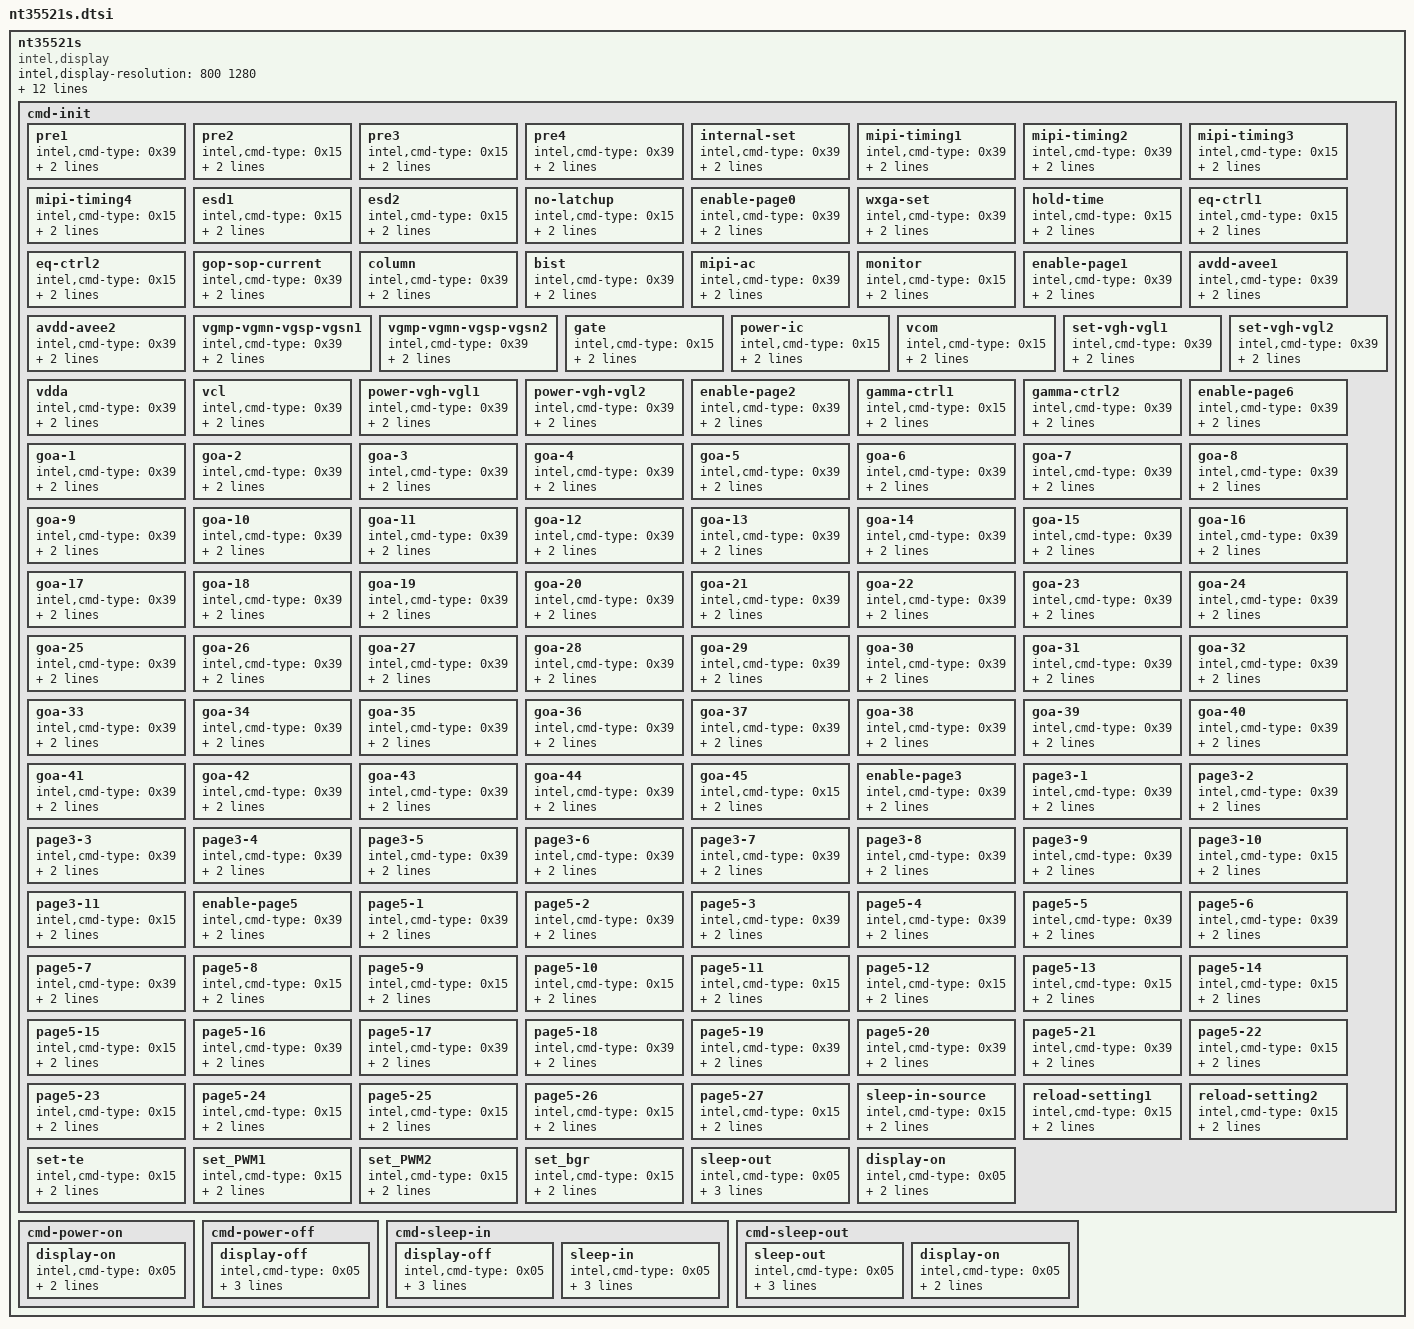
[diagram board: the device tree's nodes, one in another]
	nt35521s {
		compatible = "intel,display";
		intel,display-resolution= <800 1280>;
		intel,display-dpi= <251 251>;

		/* MIPI-DSI video mode settings */
		intel,display-vid-hfp-hs-bytes = <80>;
		intel,display-vid-hbp-hs-bytes = <80>;
		intel,display-vid-hsa-hs-bytes = <2>;
		intel,display-vid-vfp-lines = <20>;
		intel,display-vid-vbp-lines = <20>;
		intel,display-vid-vsa-lines = <2>;

		intel,display-vid-mode = "pulses";
		intel,display-vid-id = <0>;
		intel,display-vid-pixel = "24packed";
		intel,display-vid-fill_buf_to = <0x1F>;

		intel,display-reset = <1 1 0 5 1 50>;

		cmd-init {
			pre1 {
				intel,cmd-type = <0x39>;
				intel,cmd-data = <0xFF 0xAA 0x55 0x25 0x01>;
				intel,cmd-lp = <1>;
			};
			pre2 {
				intel,cmd-type = <0x15>;
				intel,cmd-data = <0x6F 0x07>;
				intel,cmd-lp = <1>;
			};
			pre3 {
				intel,cmd-type = <0x15>;
				intel,cmd-data = <0xF9 0x2B>;
				intel,cmd-lp = <1>;
			};
			pre4 {
				intel,cmd-type = <0x39>;
				intel,cmd-data = <0xFF 0xAA 0x55 0x25 0x00>;
				intel,cmd-lp = <1>;
			};
			internal-set {
				intel,cmd-type = <0x39>;
				intel,cmd-data = <0xFF 0xAA 0x55 0xA5 0x80>;
				intel,cmd-lp = <1>;
			};
			mipi-timing1 {
				intel,cmd-type = <0x39>;
				intel,cmd-data = <0x6F 0x11 0x00>;
				intel,cmd-lp = <1>;
			};
			mipi-timing2 {
				intel,cmd-type = <0x39>;
				intel,cmd-data = <0xF7 0x20 0x00>;
				intel,cmd-lp = <1>;
			};
			mipi-timing3 {
				intel,cmd-type = <0x15>;
 				intel,cmd-data = <0x6F 0x06>;
 				intel,cmd-lp = <1>;
			};
			mipi-timing4 {
				intel,cmd-type = <0x15>;
				intel,cmd-data = <0xF7 0xA0>;
				intel,cmd-lp = <1>;
			};
			esd1 {
				intel,cmd-type = <0x15>;
				intel,cmd-data = <0x6F 0x19>;
				intel,cmd-lp = <1>;
			};
			esd2 {
				intel,cmd-type = <0x15>;
				intel,cmd-data = <0xF7 0x12>;
				intel,cmd-lp = <1>;
			};
			no-latchup {
				intel,cmd-type = <0x15>;
				intel,cmd-data = <0xF4 0x03>;
				intel,cmd-lp = <1>;
			};
			enable-page0 {
				intel,cmd-type = <0x39>;
				intel,cmd-data = <0xF0 0x55 0xAA 0x52 0x08 0x00>;
				intel,cmd-lp = <1>;
			};
			wxga-set {
				intel,cmd-type = <0x39>;
				intel,cmd-data = <0xB1 0x64 0x01>;
				intel,cmd-lp = <1>;
			};
			hold-time {
				intel,cmd-type = <0x15>;
				intel,cmd-data = <0xB6 0x08>;
				intel,cmd-lp = <1>;
			};
			eq-ctrl1 {
				intel,cmd-type = <0x15>;
				intel,cmd-data = <0x6F 0x02>;
				intel,cmd-lp = <1>;
			};
			eq-ctrl2 {
				intel,cmd-type = <0x15>;
				intel,cmd-data = <0xB8 0x08>;
				intel,cmd-lp = <1>;
			};
			gop-sop-current {
				intel,cmd-type = <0x39>;
				intel,cmd-data = <0xBB 0x74 0x44>;
				intel,cmd-lp = <1>;
			};
			column {
				intel,cmd-type = <0x39>;
				intel,cmd-data = <0xBC 0x00 0x00>;
				intel,cmd-lp = <1>;
			};
			bist {
				intel,cmd-type = <0x39>;
				intel,cmd-data = <0xBD 0x02 0xB0 0x1E 0x1E 0x00>;
				intel,cmd-lp = <1>;
			};
			mipi-ac {
				intel,cmd-type = <0x39>;
				intel,cmd-data = <0xC5 0x01 0x07>;
				intel,cmd-lp = <1>;
			};
			monitor {
				intel,cmd-type = <0x15>;
				intel,cmd-data = <0xC8 0x83>;
				intel,cmd-lp = <1>;
			};
			enable-page1 {
				intel,cmd-type = <0x39>;
				intel,cmd-data = <0xF0 0x55 0xAA 0x52 0x08 0x01>;
				intel,cmd-lp = <1>;
			};
			avdd-avee1 {
				intel,cmd-type = <0x39>;
				intel,cmd-data = <0xB0 0x05 0x05>;
				intel,cmd-lp = <1>;
			};
			avdd-avee2 {
				intel,cmd-type = <0x39>;
				intel,cmd-data = <0xB1 0x05 0x05>;
				intel,cmd-lp = <1>;
			};
			vgmp-vgmn-vgsp-vgsn1 {
				intel,cmd-type = <0x39>;
				intel,cmd-data = <0xBC 0x88 0x01>;
				intel,cmd-lp = <1>;
			};
			vgmp-vgmn-vgsp-vgsn2 {
				intel,cmd-type = <0x39>;
				intel,cmd-data = <0xBD 0x88 0x01>;
				intel,cmd-lp = <1>;
			};
			gate {
				intel,cmd-type = <0x15>;
				intel,cmd-data = <0xCA 0x00>;
				intel,cmd-lp = <1>;
			};
			power-ic {
				intel,cmd-type = <0x15>;
				intel,cmd-data = <0xC0 0x04>;
				intel,cmd-lp = <1>;
			};
			vcom {
				intel,cmd-type = <0x15>;
				intel,cmd-data = <0xBE 0x60>;
				intel,cmd-lp = <1>;
			};
			set-vgh-vgl1 {
				intel,cmd-type = <0x39>;
				intel,cmd-data = <0xB3 0x2D 0x2D>;
				intel,cmd-lp = <1>;
			};
			set-vgh-vgl2 {
				intel,cmd-type = <0x39>;
				intel,cmd-data = <0xB4 0x19 0x19>;
				intel,cmd-lp = <1>;
			};
			vdda {
				intel,cmd-type = <0x39>;
				intel,cmd-data = <0xB6 0x05 0x05>;
				intel,cmd-lp = <1>;
			};
			vcl {
				intel,cmd-type = <0x39>;
				intel,cmd-data = <0xB8 0x05 0x05>;
				intel,cmd-lp = <1>;
			};
			power-vgh-vgl1 {
				intel,cmd-type = <0x39>;
				intel,cmd-data = <0xB9 0x46 0x46>;
				intel,cmd-lp = <1>;
			};
			power-vgh-vgl2 {
				intel,cmd-type = <0x39>;
				intel,cmd-data = <0xBA 0x25 0x25>;
				intel,cmd-lp = <1>;
			};
			enable-page2 {
				intel,cmd-type = <0x39>;
				intel,cmd-data = <0xF0 0x55 0xAA 0x52 0x08 0x02>;
				intel,cmd-lp = <1>;
			};
			gamma-ctrl1 {
				intel,cmd-type = <0x15>;
				intel,cmd-data = <0xEE 0x00>;
				intel,cmd-lp = <1>;
			};
			gamma-ctrl2 {
				intel,cmd-type = <0x39>;
				intel,cmd-data = <0xEF 0x09 0x06 0x15 0x18>;
				intel,cmd-lp = <1>;
			};
			enable-page6 {
				intel,cmd-type = <0x39>;
				intel,cmd-data = <0xF0 0x55 0xAA 0x52 0x08 0x06>;
				intel,cmd-lp = <1>;
			};
			goa-1 {
				intel,cmd-type = <0x39>;
				intel,cmd-data = <0xB0 0x0B 0x2E>;
				intel,cmd-lp = <1>;
			};
			goa-2 {
				intel,cmd-type = <0x39>;
				intel,cmd-data = <0xB1 0x2E 0x09>;
				intel,cmd-lp = <1>;
			};
			goa-3 {
				intel,cmd-type = <0x39>;
				intel,cmd-data = <0xB2 0x2A 0x29>;
				intel,cmd-lp = <1>;
			};
			goa-4 {
				intel,cmd-type = <0x39>;
				intel,cmd-data = <0xB3 0x1B 0x19>;
				intel,cmd-lp = <1>;
			};
			goa-5 {
				intel,cmd-type = <0x39>;
				intel,cmd-data = <0xB4 0x17 0x15>;
				intel,cmd-lp = <1>;
			};
			goa-6 {
				intel,cmd-type = <0x39>;
				intel,cmd-data = <0xB5 0x13 0x11>;
				intel,cmd-lp = <1>;
			};
			goa-7 {
				intel,cmd-type = <0x39>;
				intel,cmd-data = <0xB6 0x01 0x2E>;
				intel,cmd-lp = <1>;
			};
			goa-8 {
				intel,cmd-type = <0x39>;
				intel,cmd-data = <0xB7 0x2E 0x2E>;
				intel,cmd-lp = <1>;
			};
			goa-9 {
				intel,cmd-type = <0x39>;
				intel,cmd-data = <0xB8 0x2E 0x2E>;
				intel,cmd-lp = <1>;
			};
			goa-10 {
				intel,cmd-type = <0x39>;
				intel,cmd-data = <0xB9 0x2E 0x2E>;
				intel,cmd-lp = <1>;
			};
			goa-11 {
				intel,cmd-type = <0x39>;
				intel,cmd-data = <0xBA 0x2E 0x2E>;
				intel,cmd-lp = <1>;
			};
			goa-12 {
				intel,cmd-type = <0x39>;
				intel,cmd-data = <0xBB 0x2E 0x2E>;
				intel,cmd-lp = <1>;
			};
			goa-13 {
				intel,cmd-type = <0x39>;
				intel,cmd-data = <0xBC 0x2E 0x2E>;
				intel,cmd-lp = <1>;
			};
			goa-14 {
				intel,cmd-type = <0x39>;
				intel,cmd-data = <0xBD 0x2E 0x00>;
				intel,cmd-lp = <1>;
			};
			goa-15 {
				intel,cmd-type = <0x39>;
				intel,cmd-data = <0xBE 0x10 0x12>;
				intel,cmd-lp = <1>;
			};
			goa-16 {
				intel,cmd-type = <0x39>;
				intel,cmd-data = <0xBF 0x14 0x16>;
				intel,cmd-lp = <1>;
			};
			goa-17 {
				intel,cmd-type = <0x39>;
				intel,cmd-data = <0xC0 0x18 0x1A>;
				intel,cmd-lp = <1>;
			};
			goa-18 {
				intel,cmd-type = <0x39>;
				intel,cmd-data = <0xC1 0x29 0x2A>;
				intel,cmd-lp = <1>;
			};
			goa-19 {
				intel,cmd-type = <0x39>;
				intel,cmd-data = <0xC2 0x08 0x2E>;
				intel,cmd-lp = <1>;
			};
			goa-20 {
				intel,cmd-type = <0x39>;
				intel,cmd-data = <0xC3 0x2E 0x0A>;
				intel,cmd-lp = <1>;
			};
			goa-21 {
				intel,cmd-type = <0x39>;
				intel,cmd-data = <0xE5 0x2E 0x2E>;
				intel,cmd-lp = <1>;
			};
			goa-22 {
				intel,cmd-type = <0x39>;
				intel,cmd-data = <0xC4 0x0A 0x2E>;
				intel,cmd-lp = <1>;
			};
			goa-23 {
				intel,cmd-type = <0x39>;
				intel,cmd-data = <0xC5 0x2E 0x00>;
				intel,cmd-lp = <1>;
			};
			goa-24 {
				intel,cmd-type = <0x39>;
				intel,cmd-data = <0xC6 0x2A 0x29>;
				intel,cmd-lp = <1>;
			};
			goa-25 {
				intel,cmd-type = <0x39>;
				intel,cmd-data = <0xC7 0x10 0x12>;
				intel,cmd-lp = <1>;
			};
			goa-26 {
				intel,cmd-type = <0x39>;
				intel,cmd-data = <0xC8 0x14 0x16>;
				intel,cmd-lp = <1>;
			};
			goa-27 {
				intel,cmd-type = <0x39>;
				intel,cmd-data = <0xC9 0x18 0x1A>;
				intel,cmd-lp = <1>;
			};
			goa-28 {
				intel,cmd-type = <0x39>;
				intel,cmd-data = <0xCA 0x08 0x2E>;
				intel,cmd-lp = <1>;
			};
			goa-29 {
				intel,cmd-type = <0x39>;
				intel,cmd-data = <0xCB 0x2E 0x2E>;
				intel,cmd-lp = <1>;
			};
			goa-30 {
				intel,cmd-type = <0x39>;
				intel,cmd-data = <0xCC 0x2E 0x2E>;
				intel,cmd-lp = <1>;
			};
			goa-31 {
				intel,cmd-type = <0x39>;
				intel,cmd-data = <0xCD 0x2E 0x2E>;
				intel,cmd-lp = <1>;
			};
			goa-32 {
				intel,cmd-type = <0x39>;
				intel,cmd-data = <0xCE 0x2E 0x2E>;
				intel,cmd-lp = <1>;
			};
			goa-33 {
				intel,cmd-type = <0x39>;
				intel,cmd-data = <0xCF 0x2E 0x2E>;
				intel,cmd-lp = <1>;
			};
			goa-34 {
				intel,cmd-type = <0x39>;
				intel,cmd-data = <0xD0 0x2E 0x2E>;
				intel,cmd-lp = <1>;
			};
			goa-35 {
				intel,cmd-type = <0x39>;
				intel,cmd-data = <0xD1 0x2E 0x09>;
				intel,cmd-lp = <1>;
			};
			goa-36 {
				intel,cmd-type = <0x39>;
				intel,cmd-data = <0xD2 0x1B 0x19>;
				intel,cmd-lp = <1>;
			};
			goa-37 {
				intel,cmd-type = <0x39>;
				intel,cmd-data = <0xD3 0x17 0x15>;
				intel,cmd-lp = <1>;
			};
			goa-38 {
				intel,cmd-type = <0x39>;
				intel,cmd-data = <0xD4 0x13 0x11>;
				intel,cmd-lp = <1>;
			};
			goa-39 {
				intel,cmd-type = <0x39>;
				intel,cmd-data = <0xD5 0x29 0x2A>;
				intel,cmd-lp = <1>;
			};
			goa-40 {
				intel,cmd-type = <0x39>;
				intel,cmd-data = <0xD6 0x01 0x2E>;
				intel,cmd-lp = <1>;
			};
			goa-41 {
				intel,cmd-type = <0x39>;
				intel,cmd-data = <0xD7 0x2E 0x0B>;
				intel,cmd-lp = <1>;
			};
			goa-42 {
				intel,cmd-type = <0x39>;
				intel,cmd-data = <0xE6 0x2E 0x2E>;
				intel,cmd-lp = <1>;
			};
			goa-43 {
				intel,cmd-type = <0x39>;
				intel,cmd-data = <0xD8 0x00 0x00 0x00 0x00 0x00>;
				intel,cmd-lp = <1>;
			};
			goa-44 {
				intel,cmd-type = <0x39>;
				intel,cmd-data = <0xD9 0x00 0x00 0x00 0x00 0x00>;
				intel,cmd-lp = <1>;
			};
			goa-45 {
				intel,cmd-type = <0x15>;
				intel,cmd-data = <0xE7 0x00>;
				intel,cmd-lp = <1>;
			};
			enable-page3 {
				intel,cmd-type = <0x39>;
				intel,cmd-data = <0xF0 0x55 0xAA 0x52 0x08 0x03>;
				intel,cmd-lp = <1>;
			};
			page3-1 {
				intel,cmd-type = <0x39>;
				intel,cmd-data = <0xB0 0x20 0x00>;
				intel,cmd-lp = <1>;
			};
			page3-2 {
				intel,cmd-type = <0x39>;
				intel,cmd-data = <0xB1 0x20 0x00>;
				intel,cmd-lp = <1>;
			};
			page3-3 {
				intel,cmd-type = <0x39>;
				intel,cmd-data = <0xB2 0x05 0x00 0x00 0x00 0x00>;
				intel,cmd-lp = <1>;
			};
			page3-4 {
				intel,cmd-type = <0x39>;
				intel,cmd-data = <0xB6 0x05 0x00 0x00 0x00 0x00>;
				intel,cmd-lp = <1>;
			};
			page3-5 {
				intel,cmd-type = <0x39>;
				intel,cmd-data = <0xB7 0x05 0x00 0x00 0x00 0x00>;
				intel,cmd-lp = <1>;
			};
			page3-6 {
				intel,cmd-type = <0x39>;
				intel,cmd-data = <0xBA 0x57 0x00 0x00 0x00 0x00>;
				intel,cmd-lp = <1>;
			};
			page3-7 {
				intel,cmd-type = <0x39>;
				intel,cmd-data = <0xBB 0x57 0x00 0x00 0x00 0x00>;
				intel,cmd-lp = <1>;
			};
			page3-8 {
				intel,cmd-type = <0x39>;
				intel,cmd-data = <0xC0 0x00 0x00 0x00 0x00>;
				intel,cmd-lp = <1>;
			};
			page3-9 {
				intel,cmd-type = <0x39>;
				intel,cmd-data = <0xC1 0x00 0x00 0x00 0x00>;
				intel,cmd-lp = <1>;
			};
			page3-10 {
				intel,cmd-type = <0x15>;
				intel,cmd-data = <0xC4 0x60>;
				intel,cmd-lp = <1>;
			};
			page3-11 {
				intel,cmd-type = <0x15>;
				intel,cmd-data = <0xC5 0x40>;
				intel,cmd-lp = <1>;
			};
			enable-page5 {
				intel,cmd-type = <0x39>;
				intel,cmd-data = <0xF0 0x55 0xAA 0x52 0x08 0x05>;
				intel,cmd-lp = <1>;
			};
			page5-1 {
				intel,cmd-type = <0x39>;
				intel,cmd-data = <0xBD 0x03 0x01 0x03 0x03 0x03>;
				intel,cmd-lp = <1>;
			};
			page5-2 {
				intel,cmd-type = <0x39>;
				intel,cmd-data = <0xB0 0x17 0x06>;
				intel,cmd-lp = <1>;
			};
			page5-3 {
				intel,cmd-type = <0x39>;
				intel,cmd-data = <0xB1 0x17 0x06>;
				intel,cmd-lp = <1>;
			};
			page5-4 {
				intel,cmd-type = <0x39>;
				intel,cmd-data = <0xB2 0x17 0x06>;
				intel,cmd-lp = <1>;
			};
			page5-5 {
				intel,cmd-type = <0x39>;
				intel,cmd-data = <0xB3 0x17 0x06>;
				intel,cmd-lp = <1>;
			};
			page5-6 {
				intel,cmd-type = <0x39>;
				intel,cmd-data = <0xB4 0x17 0x06>;
				intel,cmd-lp = <1>;
			};
			page5-7 {
				intel,cmd-type = <0x39>;
				intel,cmd-data = <0xB5 0x17 0x06>;
				intel,cmd-lp = <1>;
			};
			page5-8 {
				intel,cmd-type = <0x15>;
				intel,cmd-data = <0xB8 0x00>;
				intel,cmd-lp = <1>;
			};
			page5-9 {
				intel,cmd-type = <0x15>;
				intel,cmd-data = <0xB9 0x00>;
				intel,cmd-lp = <1>;
			};
			page5-10 {
				intel,cmd-type = <0x15>;
				intel,cmd-data = <0xBA 0x00>;
				intel,cmd-lp = <1>;
			};
			page5-11 {
				intel,cmd-type = <0x15>;
				intel,cmd-data = <0xBB 0x02>;
				intel,cmd-lp = <1>;
			};
			page5-12 {
				intel,cmd-type = <0x15>;
				intel,cmd-data = <0xBC 0x00>;
				intel,cmd-lp = <1>;
			};
			page5-13 {
				intel,cmd-type = <0x15>;
				intel,cmd-data = <0xC0 0x07>;
				intel,cmd-lp = <1>;
			};
			page5-14 {
				intel,cmd-type = <0x15>;
				intel,cmd-data = <0xC4 0x80>;
				intel,cmd-lp = <1>;
			};
			page5-15 {
				intel,cmd-type = <0x15>;
				intel,cmd-data = <0xC5 0xA4>;
				intel,cmd-lp = <1>;
			};
			page5-16 {
				intel,cmd-type = <0x39>;
				intel,cmd-data = <0xC8 0x05 0x30>;
				intel,cmd-lp = <1>;
			};
			page5-17 {
				intel,cmd-type = <0x39>;
				intel,cmd-data = <0xC9 0x01 0x31>;
				intel,cmd-lp = <1>;
			};
			page5-18 {
				intel,cmd-type = <0x39>;
				intel,cmd-data = <0xCC 0x00 0x00 0x3C>;
				intel,cmd-lp = <1>;
			};
			page5-19 {
				intel,cmd-type = <0x39>;
				intel,cmd-data = <0xCD 0x00 0x00 0x3C>;
				intel,cmd-lp = <1>;
			};
			page5-20 {
				intel,cmd-type = <0x39>;
				intel,cmd-data = <0xD1 0x00 0x05 0x09 0x07 0x10>;
				intel,cmd-lp = <1>;
			};
			page5-21 {
				intel,cmd-type = <0x39>;
				intel,cmd-data = <0xD2 0x00 0x05 0x0E 0x07 0x10>;
				intel,cmd-lp = <1>;
			};
			page5-22 {
				intel,cmd-type = <0x15>;
				intel,cmd-data = <0xE5 0x06>;
				intel,cmd-lp = <1>;
			};
			page5-23 {
				intel,cmd-type = <0x15>;
				intel,cmd-data = <0xE6 0x06>;
				intel,cmd-lp = <1>;
			};
			page5-24 {
				intel,cmd-type = <0x15>;
				intel,cmd-data = <0xE7 0x06>;
				intel,cmd-lp = <1>;
			};
			page5-25 {
				intel,cmd-type = <0x15>;
				intel,cmd-data = <0xE8 0x06>;
				intel,cmd-lp = <1>;
			};
			page5-26 {
				intel,cmd-type = <0x15>;
				intel,cmd-data = <0xE9 0x06>;
				intel,cmd-lp = <1>;
			};
			page5-27 {
				intel,cmd-type = <0x15>;
				intel,cmd-data = <0xEA 0x06>;
				intel,cmd-lp = <1>;
			};
			sleep-in-source {
				intel,cmd-type = <0x15>;
				intel,cmd-data = <0xED 0x30>;
				intel,cmd-lp = <1>;
			};
			reload-setting1 {
				intel,cmd-type = <0x15>;
				intel,cmd-data = <0x6F 0x11>;
				intel,cmd-lp = <1>;
			};
			reload-setting2 {
				intel,cmd-type = <0x15>;
				intel,cmd-data = <0xF3 0x01>;
				intel,cmd-lp = <1>;
			};
			set-te {
				intel,cmd-type = <0x15>;
				intel,cmd-data = <0x35 0x00>;
				intel,cmd-lp = <1>;
			};
			set_PWM1 {
				intel,cmd-type = <0x15>;
				intel,cmd-data = <0x53 0x2C>;
				intel,cmd-lp = <1>;
			};
			set_PWM2 {
				intel,cmd-type = <0x15>;
				intel,cmd-data = <0x51 0xFF>;
				intel,cmd-lp = <1>;
			};
			set_bgr {
				intel,cmd-type = <0x15>;
				intel,cmd-data = <0x36 0x08>;
				intel,cmd-lp = <1>;
			};
			sleep-out{
				intel,cmd-type = <0x05>;
				intel,cmd-data = <0x11>;
				intel,cmd-lp = <1>;
				intel,cmd-delay = <120>;
			};
			display-on{
				intel,cmd-type = <0x05>;
				intel,cmd-data = <0x29>;
				intel,cmd-lp = <1>;
			};
		};
		cmd-power-on {
			display-on{
				intel,cmd-type = <0x05>;
				intel,cmd-data = <0x29>;
				intel,cmd-lp = <1>;
			};
		};

		cmd-power-off {
			display-off{
				intel,cmd-type = <0x05>;
				intel,cmd-data = <0x28>;
				intel,cmd-lp = <1>;
				intel,cmd-delay = <40>;
			};
		};

		cmd-sleep-in {
			display-off{
				intel,cmd-type = <0x05>;
				intel,cmd-data = <0x28>;
				intel,cmd-lp = <1>;
				intel,cmd-delay = <40>;
			};
			sleep-in{
				intel,cmd-type = <0x05>;
				intel,cmd-data = <0x10>;
				intel,cmd-lp = <1>;
				intel,cmd-delay = <100>;
			};
		};

		cmd-sleep-out {
			sleep-out{
				intel,cmd-type = <0x05>;
				intel,cmd-data = <0x11>;
				intel,cmd-lp = <1>;
				intel,cmd-delay = <120>;
			};
			display-on{
				intel,cmd-type = <0x05>;
				intel,cmd-data = <0x29>;
				intel,cmd-lp = <1>;
			};
		};
	};
